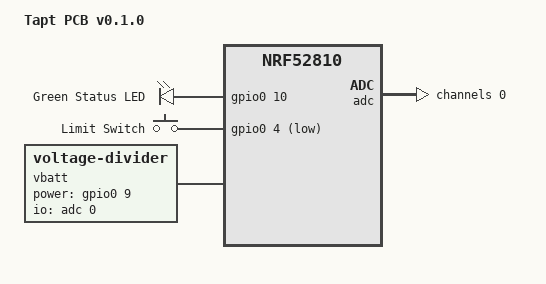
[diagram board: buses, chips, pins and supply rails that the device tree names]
/dts-v1/;
#include <nordic/nrf52810_qfaa.dtsi>

/ {
	model = "Tapt PCB v0.1.0";
	compatible = "tapt";

	aliases {
		status-led = &status_led;
		limit-switch = &limit_switch;
	};

	chosen {
		// zephyr,console = &uart0;
		// zephyr,shell-uart = &uart0;
		zephyr,sram = &sram0;
		zephyr,flash = &flash0;
	};

	leds {
		compatible = "gpio-leds";

		status_led: status_led {
			gpios = <&gpio0 10 GPIO_ACTIVE_HIGH>;
			label = "Green Status LED";
		};
	};

	buttons {
		compatible = "gpio-keys";

		limit_switch: limit_switch {
			label = "Limit Switch";
			// onboard pullup
			gpios = <&gpio0 4 GPIO_ACTIVE_LOW>;
		};
	};

	vbatt {
		compatible = "voltage-divider";
		status = "okay";
		// GPIO 6 / ADC 3
		io-channels = <&adc 0>;
		// 1M + 1M
    output-ohms = <1000000>;
    full-ohms = <(1000000 + 1000000)>;
		power-gpios = <&gpio0 9 0>;
	};
};

&reg {
	regulator-initial-mode = <NRF5X_REG_MODE_DCDC>;
};

/* &pinctrl {
  uart0_default: uart0_default {
		group1 {
			psels = <NRF_PSEL(UART_TX, 0, 6)>,
				<NRF_PSEL(UART_RX, 0, 8)>;
		};
	};

  uart0_sleep: uart0_sleep {
		group1 {
			psels = <NRF_PSEL(UART_TX, 0, 6)>,
				<NRF_PSEL(UART_RX, 0, 8)>;
			low-power-enable;
		};
	};
}; */

&adc {
	status = "okay";
	#address-cells = <1>;
	#size-cells = <0>;

	channel@0 {
		reg = <0>;
		// max 2V, our dividers results in 1.85V
		zephyr,gain = "ADC_GAIN_1_4";
		zephyr,reference = "ADC_REF_INTERNAL";
		zephyr,input-positive = <NRF_SAADC_AIN3>; // P0.05
		// defaults from battery channel
		zephyr,resolution = <14>;
		zephyr,oversampling = <4>;
		zephyr,acquisition-time = <ADC_ACQ_TIME(ADC_ACQ_TIME_MICROSECONDS, 40)>;
	};
};

&uicr {
	gpio-as-nreset;
};

&gpiote {
	status = "okay";
	wakeup-source;
};

&gpio0 {
	status = "okay";
};

/* &uart0 {
	compatible = "nordic,nrf-uarte";
	status = "disabled";
	current-speed = <115200>;
	pinctrl-0 = <&uart0_default>;
	pinctrl-1 = <&uart0_sleep>;
	pinctrl-names = "default", "sleep";
}; */
